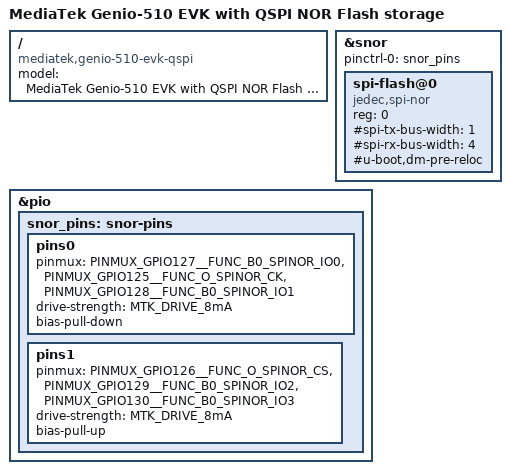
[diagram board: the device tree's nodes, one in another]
// SPDX-License-Identifier: GPL-2.0 OR MIT
/*
 * Copyright (C) 2024 MediaTek INC.
 * Author: Macpaul Lin <macpaul.lin@mediatek.com>
 */

/dts-v1/;

#include "genio-510-evk-common.dtsi"

/ {
	model = "MediaTek Genio-510 EVK with QSPI NOR Flash storage";
	compatible = "mediatek,genio-510-evk-qspi", "mediatek,mt8370";
};

&snor {
	pinctrl-names = "default";
	pinctrl-0 = <&snor_pins>;
	status = "okay";

	spi-flash@0{
		compatible = "jedec,spi-nor";
		reg = <0>;
		#spi-tx-bus-width = <1>;
		#spi-rx-bus-width = <4>;
		#u-boot,dm-pre-reloc;
	};
};

&pio {
	snor_pins: snor-pins {
		pins0 {
			pinmux = <PINMUX_GPIO127__FUNC_B0_SPINOR_IO0>,
				 <PINMUX_GPIO125__FUNC_O_SPINOR_CK>,
				 <PINMUX_GPIO128__FUNC_B0_SPINOR_IO1>;
			drive-strength = <MTK_DRIVE_8mA>;
			bias-pull-down;
		};

		pins1 {
			pinmux = <PINMUX_GPIO126__FUNC_O_SPINOR_CS>,
				 <PINMUX_GPIO129__FUNC_B0_SPINOR_IO2>,
				 <PINMUX_GPIO130__FUNC_B0_SPINOR_IO3>;
			drive-strength = <MTK_DRIVE_8mA>;
			bias-pull-up;
		};
	};
};
